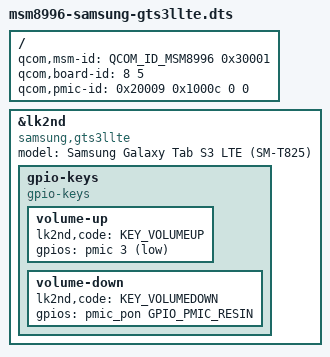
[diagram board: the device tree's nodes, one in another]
// SPDX-License-Identifier: BSD-3-Clause
// Adapted from wh1ter0z3/gts3lwifi-mainline's LTE entry.
// IDs verified against the connected SM-T825 rev05 live DTB.
#include <skeleton64.dtsi>
#include <lk2nd.dtsi>
/ {
	qcom,msm-id = <QCOM_ID_MSM8996 0x30001>;
	qcom,board-id = <8 5>;
	qcom,pmic-id = <0x20009 0x1000c 0 0>;
};
&lk2nd {
	model = "Samsung Galaxy Tab S3 LTE (SM-T825)";
	compatible = "samsung,gts3llte";
	gpio-keys {
		compatible = "gpio-keys";
		volume-up {
			lk2nd,code = <KEY_VOLUMEUP>;
			gpios = <&pmic 3 (GPIO_ACTIVE_LOW | GPIO_PULL_UP)>;
		};
		volume-down {
			lk2nd,code = <KEY_VOLUMEDOWN>;
			gpios = <&pmic_pon GPIO_PMIC_RESIN 0>;
		};
	};
};
